LIN_description_file;
LIN_protocol_version = "2.0";
LIN_language_version = "2.0";
LIN_speed = 19.2 kbps;

Nodes {
  Master: commander, 10 ms, 0.9 ms;
  Slaves: eval_0;
}

Signals {
  eval_0_rgb_r: 8, 0, commander, eval_0;
  eval_0_rgb_g: 8, 0, commander, eval_0;
  eval_0_rgb_b: 8, 0, commander, eval_0;

  eval_0_led0: 1, 0, commander, eval_0;
  eval_0_led1: 1, 0, commander, eval_0;
  eval_0_led2: 1, 0, commander, eval_0;
  eval_0_led3: 1, 0, commander, eval_0;

  eval_0_photores_mV: 16, 0, eval_0, commander;
}

Frames {
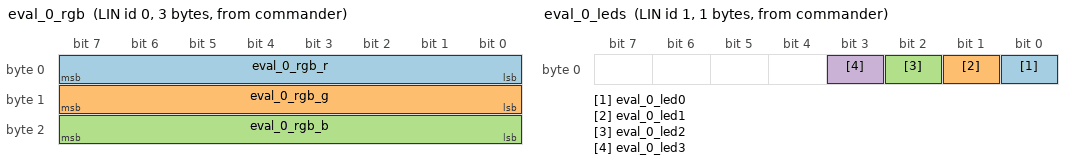
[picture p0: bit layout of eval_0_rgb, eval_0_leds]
  eval_0_rgb: 0, commander, 3 {
    eval_0_rgb_r, 0;
    eval_0_rgb_g, 8;
    eval_0_rgb_b, 16;
  }

  eval_0_leds: 1, commander, 1 {
    eval_0_led0, 0;
    eval_0_led1, 1;
    eval_0_led2, 2;
    eval_0_led3, 3;
  }

  eval_0_photores: 2, eval_0, 2 {
    eval_0_photores_mV, 0;
  }
}

Node_attributes {
  eval_0 {
    LIN_protocol = 2.0;
    configured_NAD = 0;
  }
}
